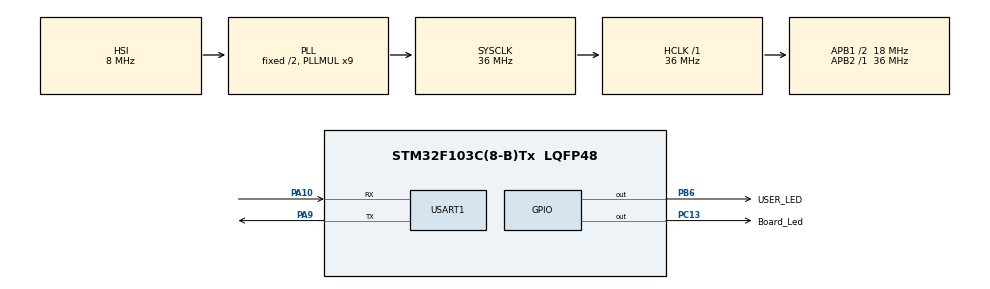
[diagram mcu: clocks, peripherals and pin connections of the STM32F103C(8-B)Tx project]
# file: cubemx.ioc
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FREERTOS.Tasks01=defaultTask,0,128,StartDefaultTask,Default,NULL,Dynamic,NULL,NULL;BOARD_LEDTask,-3,128,StartBOARD_LED,Default,NULL,Dynamic,NULL,NULL;USER_LEDTask,-3,128,StartUSER_LED,Default,NULL,Dynamic,NULL,NULL
Mcu.Family=STM32F1
Mcu.Name=STM32F103C(8-B)Tx
Mcu.Package=LQFP48
NVIC.PriorityGroup=NVIC_PRIORITYGROUP_4
NVIC.TIM1_UP_IRQn=true\:15\:0\:false\:false\:true\:false\:false\:true\:true
NVIC.TimeBase=TIM1_UP_IRQn
NVIC.TimeBaseIP=TIM1
PA10.Mode=Asynchronous
PA10.Signal=USART1_RX
PA13.Mode=Serial_Wire
PA13.Signal=SYS_JTMS-SWDIO
PA14.Mode=Serial_Wire
PA14.Signal=SYS_JTCK-SWCLK
PA9.Mode=Asynchronous
PA9.Signal=USART1_TX
PB6.GPIO_Label=USER_LED
PB6.Signal=GPIO_Output
PC13-TAMPER-RTC.GPIO_Label=Board_Led
PC13-TAMPER-RTC.Signal=GPIO_Output
ProjectManager.HeapSize=0x200
ProjectManager.StackSize=0x400
ProjectManager.TargetToolchain=Makefile
RCC.AHBFreq_Value=36000000
RCC.APB1CLKDivider=RCC_HCLK_DIV2
RCC.APB1Freq_Value=18000000
RCC.APB1TimFreq_Value=36000000
RCC.APB2Freq_Value=36000000
RCC.APB2TimFreq_Value=36000000
RCC.HCLKFreq_Value=36000000
RCC.PLLMUL=RCC_PLL_MUL9
RCC.SYSCLKFreq_VALUE=36000000
RCC.SYSCLKSource=RCC_SYSCLKSOURCE_PLLCLK
RCC.USBFreq_Value=36000000
USART1.VirtualMode=VM_ASYNC
VP_FREERTOS_VS_CMSIS_V1.Mode=CMSIS_V1
VP_SYS_VS_tim1.Mode=TIM1
board=custom

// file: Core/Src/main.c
/* USER CODE BEGIN Header */
/**
  ******************************************************************************
  * @file           : main.c
  * @brief          : Main program body
  ******************************************************************************
  * @attention
  *
  * Copyright (c) 2023 STMicroelectronics.
  * All rights reserved.
  *
  * This software is licensed under terms that can be found in the LICENSE file
  * in the root directory of this software component.
  * If no LICENSE file comes with this software, it is provided AS-IS.
  *
  ******************************************************************************
  */
/* USER CODE END Header */
#include "main.h"
#include "cmsis_os.h"
#include "usart.h"
#include "gpio.h"

void SystemClock_Config(void);
void MX_FREERTOS_Init(void);

int main(void)
{

  /* MCU Configuration--------------------------------------------------------*/

  /* Reset of all peripherals, Initializes the Flash interface and the Systick. */
  HAL_Init();

  /* Configure the system clock */
  SystemClock_Config();

  /* Initialize all configured peripherals */
  MX_GPIO_Init();
  MX_USART1_UART_Init();

  /* Call init function for freertos objects (in freertos.c) */
  // MX_FREERTOS_Init();

  /* Start scheduler */
  // osKernelStart();

  /* We should never get here as control is now taken by the scheduler */
  /* Infinite loop */
  while (1)
  {

    /* USER CODE BEGIN 3 */

    HAL_GPIO_WritePin(Board_Led_GPIO_Port,Board_Led_Pin,GPIO_PIN_RESET);
    HAL_Delay(200);
    HAL_GPIO_WritePin(Board_Led_GPIO_Port,Board_Led_Pin,GPIO_PIN_SET);
    HAL_Delay(200);
  }
  /* USER CODE END 3 */
}

void SystemClock_Config(void)
{
  RCC_OscInitTypeDef RCC_OscInitStruct = {0};
  RCC_ClkInitTypeDef RCC_ClkInitStruct = {0};

  /** Initializes the RCC Oscillators according to the specified parameters
  * in the RCC_OscInitTypeDef structure.
  */
  RCC_OscInitStruct.OscillatorType = RCC_OSCILLATORTYPE_HSI;
  RCC_OscInitStruct.HSIState = RCC_HSI_ON;
  RCC_OscInitStruct.HSICalibrationValue = RCC_HSICALIBRATION_DEFAULT;
  RCC_OscInitStruct.PLL.PLLState = RCC_PLL_ON;
  RCC_OscInitStruct.PLL.PLLSource = RCC_PLLSOURCE_HSI_DIV2;
  RCC_OscInitStruct.PLL.PLLMUL = RCC_PLL_MUL9;
  if (HAL_RCC_OscConfig(&RCC_OscInitStruct) != HAL_OK)
  {
    Error_Handler();
  }

  /** Initializes the CPU, AHB and APB buses clocks
  */
  RCC_ClkInitStruct.ClockType = RCC_CLOCKTYPE_HCLK|RCC_CLOCKTYPE_SYSCLK
                              |RCC_CLOCKTYPE_PCLK1|RCC_CLOCKTYPE_PCLK2;
  RCC_ClkInitStruct.SYSCLKSource = RCC_SYSCLKSOURCE_PLLCLK;
  RCC_ClkInitStruct.AHBCLKDivider = RCC_SYSCLK_DIV1;
  RCC_ClkInitStruct.APB1CLKDivider = RCC_HCLK_DIV2;
  RCC_ClkInitStruct.APB2CLKDivider = RCC_HCLK_DIV1;

  if (HAL_RCC_ClockConfig(&RCC_ClkInitStruct, FLASH_LATENCY_1) != HAL_OK)
  {
    Error_Handler();
  }
}

void HAL_TIM_PeriodElapsedCallback(TIM_HandleTypeDef *htim)
{
  if (htim->Instance == TIM1) {
    HAL_IncTick();
  }
}

void Error_Handler(void)
{
  __disable_irq();
  while (1)
  {
  }
}
